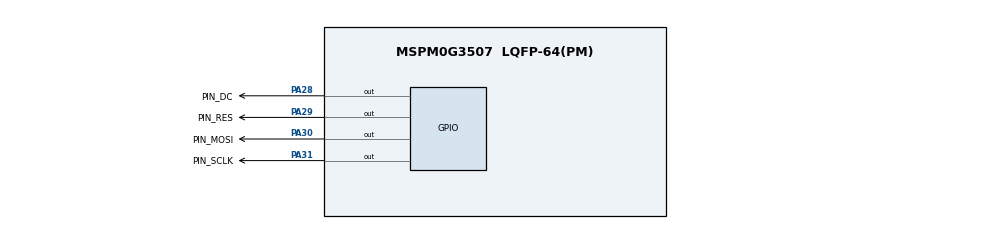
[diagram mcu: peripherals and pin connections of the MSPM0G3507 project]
/**
 * These arguments were used when this file was generated. They will be automatically applied on subsequent loads
 * via the GUI or CLI. Run CLI with '--help' for additional information on how to override these arguments.
 * @cliArgs --device "MSPM0G350X" --part "Default" --package "LQFP-64(PM)" --product "mspm0_sdk@2.03.00.07"
 * @v2CliArgs --device "MSPM0G3507" --package "LQFP-64(PM)" --product "mspm0_sdk@2.03.00.07"
 * @versions {"tool":"1.21.1+3772"}
 */

/**
 * Import the modules used in this configuration.
 */
const GPIO   = scripting.addModule("/ti/driverlib/GPIO", {}, false);
const GPIO1  = GPIO.addInstance();
const SYSCTL = scripting.addModule("/ti/driverlib/SYSCTL");

/**
 * Write custom configuration values to the imported modules.
 */
GPIO1.$name                          = "GPIO_LCD";
GPIO1.associatedPins.create(6);
GPIO1.associatedPins[0].$name        = "PIN_SCLK";
GPIO1.associatedPins[0].assignedPort = "PORTA";
GPIO1.associatedPins[0].assignedPin  = "31";
GPIO1.associatedPins[0].pin.$assign  = "PA31";
GPIO1.associatedPins[1].$name        = "PIN_MOSI";
GPIO1.associatedPins[1].assignedPort = "PORTA";
GPIO1.associatedPins[1].assignedPin  = "30";
GPIO1.associatedPins[1].pin.$assign  = "PA30";
GPIO1.associatedPins[2].$name        = "PIN_RES";
GPIO1.associatedPins[2].assignedPort = "PORTA";
GPIO1.associatedPins[2].assignedPin  = "29";
GPIO1.associatedPins[2].pin.$assign  = "PA29";
GPIO1.associatedPins[3].$name        = "PIN_DC";
GPIO1.associatedPins[3].assignedPort = "PORTA";
GPIO1.associatedPins[3].assignedPin  = "28";
GPIO1.associatedPins[3].pin.$assign  = "PA28";
GPIO1.associatedPins[4].$name        = "PIN_CS";
GPIO1.associatedPins[4].assignedPort = "PORTA";
GPIO1.associatedPins[4].assignedPin  = "1";
GPIO1.associatedPins[5].$name        = "PIN_BLK";
GPIO1.associatedPins[5].assignedPort = "PORTA";
GPIO1.associatedPins[5].assignedPin  = "0";

const Board = scripting.addModule("/ti/driverlib/Board", {}, false);

SYSCTL.forceDefaultClkConfig = true;

/**
 * Pinmux solution for unlocked pins/peripherals. This ensures that minor changes to the automatic solver in a future
 * version of the tool will not impact the pinmux you originally saw.  These lines can be completely deleted in order to
 * re-solve from scratch.
 */
GPIO1.associatedPins[4].pin.$suggestSolution = "PA1";
GPIO1.associatedPins[5].pin.$suggestSolution = "PA0";
Board.peripheral.$suggestSolution            = "DEBUGSS";
Board.peripheral.swclkPin.$suggestSolution   = "PA20";
Board.peripheral.swdioPin.$suggestSolution   = "PA19";
SYSCTL.peripheral.$suggestSolution           = "SYSCTL";
